# ESP32-P4 register map
Vendor: ESPRESSIF SYSTEMS (SHANGHAI) CO., LTD.; Series: ESP32 P-Series; File version: 3
CPU: RV32IMAFC r0p0, little endian, no MPU, FPU, 0 interrupt priority bits
Address unit: 32 bits
Registers are 32-bit, read-write, reset 0x0 unless marked. A register's access mark holds for its fields unless they carry their own. Offsets are from the block's base; [hi:lo] are bit positions.

## LP_TSENS — Low-power Temperature Sensor
Base 0x5012F000
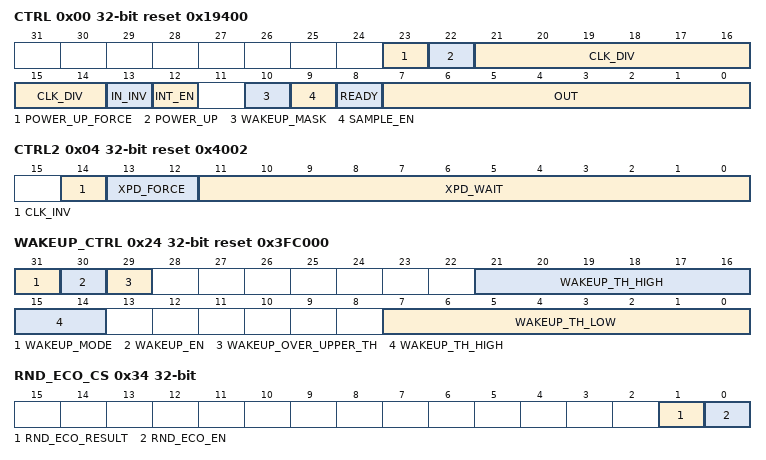
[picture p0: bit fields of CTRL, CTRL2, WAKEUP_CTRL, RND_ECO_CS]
0x00 CTRL access per field reset 0x19400 — Tsens configuration.
  [23] POWER_UP_FORCE rw — 1: dump out & power up controlled by SW, 0: by FSM.
  [22] POWER_UP rw — Temperature sensor power up.
  [21:14] CLK_DIV rw — Temperature sensor clock divider.
  [13] IN_INV rw — Invert temperature sensor data.
  [12] INT_EN rw — Enable temperature sensor to send out interrupt.
  [10] WAKEUP_MASK rw — Wake up signal mask.
  [9] SAMPLE_EN rw — Enable sample signal for wakeup module.
  [8] READY ro — Indicate temperature sensor out ready.
  [7:0] OUT ro — Temperature sensor data out.
0x04 CTRL2 reset 0x4002 — Tsens configuration.
  [14] CLK_INV, [13:12] XPD_FORCE, [11:0] XPD_WAIT
0x08 INT_RAW — Tsens interrupt raw registers.
  [0] COCPU_TSENS_WAKE — Tsens wakeup interrupt raw.
0x0C INT_ST ro — Tsens interrupt status registers.
  [0] COCPU_TSENS_WAKE — Tsens wakeup interrupt status.
0x10 INT_ENA — Tsens interrupt enable registers.
  [0] COCPU_TSENS_WAKE — Tsens wakeup interrupt enable.
0x14 INT_CLR wo — Tsens interrupt clear registers.
  [0] COCPU_TSENS_WAKE write-1-clears — Tsens wakeup interrupt clear.
0x18 CLK_CONF — Tsens regbank configuration registers.
  [0] CLK_EN — Tsens regbank clock gating enable.
0x1C INT_ENA_W1TS wo — Tsens wakeup interrupt enable assert.
  [0] COCPU_TSENS_WAKE_INT_ENA_W1TS — Write 1 to this field to assert interrupt enable.
0x20 INT_ENA_W1TC wo — Tsens wakeup interrupt enable deassert.
  [0] COCPU_TSENS_WAKE_INT_ENA_W1TC — Write 1 to this field to deassert interrupt enable.
0x24 WAKEUP_CTRL access per field reset 0x3FC000 — Tsens wakeup control registers.
  [31] WAKEUP_MODE rw — 0:absolute value comparison mode. 1: relative value comparison mode.
  [30] WAKEUP_EN rw — Tsens wakeup enable.
  [29] WAKEUP_OVER_UPPER_TH ro — Indicates that this wakeup event arose from exceeding upper threshold.
  [21:14] WAKEUP_TH_HIGH rw — Upper threshold.
  [7:0] WAKEUP_TH_LOW rw — Lower threshold.
0x28 SAMPLE_RATE reset 0x14 — Hardware automatic sampling control registers.
  [15:0] SAMPLE_RATE — Hardware automatic sampling rate.
0x2C RND_ECO_LOW
0x30 RND_ECO_HIGH reset 0xFFFFFFFF
0x34 RND_ECO_CS access per field
  [1] RND_ECO_RESULT ro, [0] RND_ECO_EN rw

## USB_WRAP — USB_WRAP Peripheral
Base 0x50080000
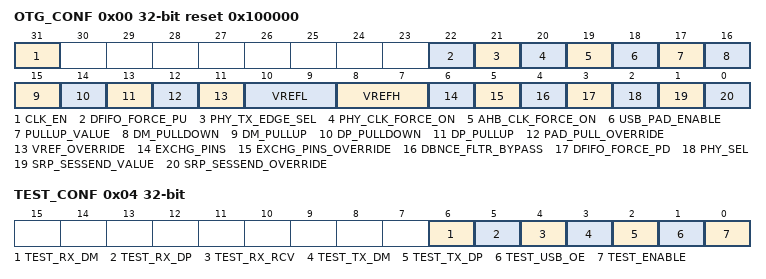
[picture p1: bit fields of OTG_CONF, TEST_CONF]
0x00 OTG_CONF reset 0x100000 — USB wrapper configuration registers.
  [31] CLK_EN — Disable auto clock gating of CSR registers.
  [22] DFIFO_FORCE_PU — Disable the dfifo to go into low power mode. The data in dfifo will not lost.
  [21] PHY_TX_EDGE_SEL — Select phy tx signal output clock edge. 1'b0: negedge, 1'b1: posedge.
  [20] PHY_CLK_FORCE_ON — Force phy clock always on.
  [19] AHB_CLK_FORCE_ON — Force ahb clock always on.
  [18] USB_PAD_ENABLE — Enable USB pad function.
  [17] PULLUP_VALUE — Controlle pullup value. 1'b0: typical value is 2.4K, 1'b1: typical value is 1.2K.
  [16] DM_PULLDOWN — Controlle USB D+ pulldown.
  [15] DM_PULLUP — Controlle USB D+ pullup.
  [14] DP_PULLDOWN — Controlle USB D+ pulldown.
  [13] DP_PULLUP — Controlle USB D+ pullup.
  [12] PAD_PULL_OVERRIDE — Enable software controlle USB D+ D- pullup pulldown.
  [11] VREF_OVERRIDE — Enable software controlle input threshold.
  [10:9] VREFL — Control single-end input low threshold,0.8V to 1.04V, step 80mV.
  [8:7] VREFH — Control single-end input high threshold,1.76V to 2V, step 80mV.
  [6] EXCHG_PINS — USB D+ D- exchange. 1'b0: don't change, 1'b1: exchange D+ D-.
  [5] EXCHG_PINS_OVERRIDE — Enable software controlle USB D+ D- exchange
  [4] DBNCE_FLTR_BYPASS — Bypass Debounce filters for avalid,bvalid,vbusvalid,session end, id signals
  [3] DFIFO_FORCE_PD — Force the dfifo to go into low power mode. The data in dfifo will not lost.
  [2] PHY_SEL — Select internal external PHY. 1'b0: Select internal PHY, 1'b1: Select external PHY.
  [1] SRP_SESSEND_VALUE — Software over-ride value of srp session end signal.
  [0] SRP_SESSEND_OVERRIDE — This bit is used to enable the software over-ride of srp session end signal. 1'b0: the signal is controlled by the chip input, 1'b1: the signal is controlled by the software.
0x04 TEST_CONF access per field — USB wrapper test configuration registers.
  [6] TEST_RX_DM ro — USB D- rx value in test.
  [5] TEST_RX_DP ro — USB D+ rx value in test.
  [4] TEST_RX_RCV ro — USB differential rx value in test.
  [3] TEST_TX_DM rw — USB D- tx value in test.
  [2] TEST_TX_DP rw — USB D+ tx value in test.
  [1] TEST_USB_OE rw — USB pad oen in test.
  [0] TEST_ENABLE rw — Enable test of the USB pad.
0x3FC DATE ro reset 0x23030504
  [31:0] USB_WRAP_DATE
